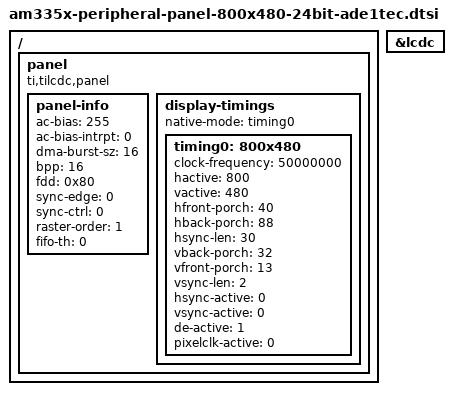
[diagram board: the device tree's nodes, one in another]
/*
 * Copyright (C) 2012 Texas Instruments Incorporated - http://www.ti.com/
 *
 * This program is free software; you can redistribute it and/or modify
 * it under the terms of the GNU General Public License version 2 as
 * published by the Free Software Foundation.
 */

&lcdc {
	status = "okay";
};

/ {
	panel {
		status = "okay";
		compatible = "ti,tilcdc,panel";
		pinctrl-names = "default";

		panel-info {
			ac-bias        = <255>;
			ac-bias-intrpt = <0>;
			dma-burst-sz   = <16>;
			bpp            = <16>;
			fdd            = <0x80>;
			sync-edge      = <0>;
			sync-ctrl      = <0>;
			raster-order   = <1>;
			fifo-th        = <0>;
		};
		display-timings {
			native-mode = <&timing0>;
			timing0: 800x480 {
				clock-frequency = <50000000>;
				hactive         = <800>;
				vactive         = <480>;
				hfront-porch    = <40>;
				hback-porch     = <88>;
				hsync-len       = <30>;
				vback-porch     = <32>;
				vfront-porch    = <13>;
				vsync-len       = <2>;
				hsync-active    = <0>;
				vsync-active    = <0>;
				de-active       = <1>;
				pixelclk-active = <0>;
			};
		};
	};
};
